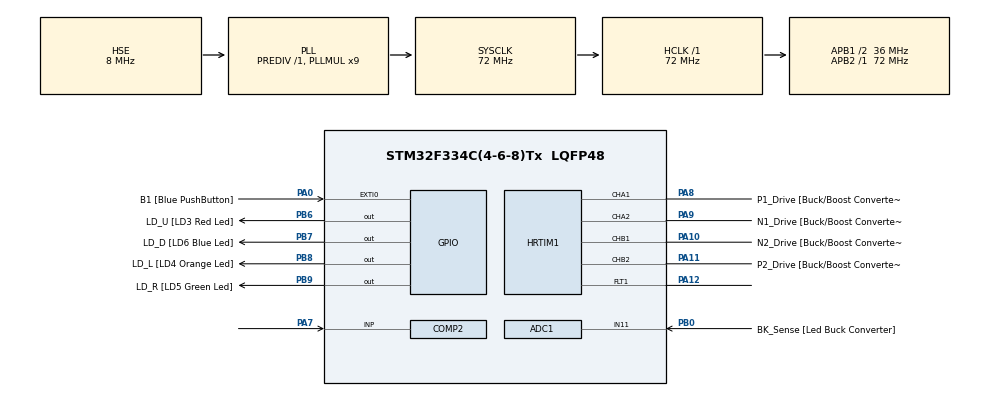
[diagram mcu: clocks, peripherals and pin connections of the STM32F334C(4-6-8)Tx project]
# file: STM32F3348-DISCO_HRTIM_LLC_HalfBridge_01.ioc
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ADC1.Channel-0\#ChannelRegularConversion=ADC_CHANNEL_11
ADC1.Channel-IN11=ADC_CHANNEL_11
ADC1.SubFamily=STM32F334x8
ADC1.master=1
COMP2.InvertingInput=COMP_INVERTINGINPUT_DAC1_CH2
HRTIM1.ADCTrigger2_Source1=HRTIM_ADCTRIGGEREVENT24_TIMERB_CMP3
HRTIM1.ADCTrigger2_Source2=HRTIM_ADCTRIGGEREVENT24_TIMERB_CMP4
HRTIM1.ADCTrigger2_Source3=HRTIM_ADCTRIGGEREVENT24_TIMERB_CMP2
HRTIM1.ADCTrigger2_Source4=HRTIM_ADCTRIGGEREVENT24_TIMERB_PERIOD
HRTIM1.ADCTrigger4_Source1=HRTIM_ADCTRIGGEREVENT24_TIMERC_CMP2
HRTIM1.ADCTrigger4_Source2=HRTIM_ADCTRIGGEREVENT24_TIMERC_CMP3
HRTIM1.ADCTrigger4_Source3=HRTIM_ADCTRIGGEREVENT24_TIMERC_CMP4
HRTIM1.ADCTrigger4_Source4=HRTIM_ADCTRIGGEREVENT24_TIMERC_PERIOD
HRTIM1.ADCTrigger_Id2=HRTIM_ADCTRIGGER_2
HRTIM1.ADCTrigger_Id4=HRTIM_ADCTRIGGER_4
HRTIM1.CompareUnit1-MasterTimer=HRTIM_COMPAREUNIT_1
HRTIM1.CompareUnit1-Output_TA1TA2=HRTIM_COMPAREUNIT_1
HRTIM1.CompareUnit1-Output_TB1TB2=HRTIM_COMPAREUNIT_1
HRTIM1.CompareUnit2-MasterTimer=HRTIM_COMPAREUNIT_2
HRTIM1.CompareUnit2-No_output_TC=HRTIM_COMPAREUNIT_2
HRTIM1.CompareUnit2-Output_TB1TB2=HRTIM_COMPAREUNIT_2
HRTIM1.CompareUnit3-MasterTimer=HRTIM_COMPAREUNIT_3
HRTIM1.CompareUnit3-No_output_TC=HRTIM_COMPAREUNIT_3
HRTIM1.CompareUnit3-Output_TB1TB2=HRTIM_COMPAREUNIT_3
HRTIM1.CompareUnit4-MasterTimer=HRTIM_COMPAREUNIT_4
HRTIM1.CompareUnit4-No_output_TC=HRTIM_COMPAREUNIT_4
HRTIM1.CompareUnit4-Output_TB1TB2=HRTIM_COMPAREUNIT_4
HRTIM1.CompareValue1-Output_TB1TB2=(15 * LLC_PWM_PERIOD)/100
HRTIM1.CompareValue2-MasterTimer=(35 * LLC_PWM_PERIOD)/100 - ADC_CONVERSION_TIME
HRTIM1.CompareValue2-No_output_TC=(65 * LLC_PWM_PERIOD)/100 - ADC_CONVERSION_TIME
HRTIM1.CompareValue2-Output_TB1TB2=(35 * LLC_PWM_PERIOD)/100
HRTIM1.CompareValue3-MasterTimer=(65 * LLC_PWM_PERIOD)/100
HRTIM1.CompareValue3-No_output_TC=(65 * LLC_PWM_PERIOD)/100 + ADC_CONVERSION_TIME
HRTIM1.CompareValue3-Output_TB1TB2=(15 * LLC_PWM_PERIOD)/100 - ADC_CONVERSION_TIME
HRTIM1.CompareValue4-MasterTimer=(85 * LLC_PWM_PERIOD)/100
HRTIM1.CompareValue4-No_output_TC=(85 * LLC_PWM_PERIOD)/100 - ADC_CONVERSION_TIME
HRTIM1.CompareValue4-Output_TB1TB2=(15 * LLC_PWM_PERIOD)/100 + ADC_CONVERSION_TIME
HRTIM1.DeadTimeInsertion-Output_TA1TA2=HRTIM_TIMDEADTIMEINSERTION_ENABLED
HRTIM1.DeadTimeInsertion-Output_TB1TB2=HRTIM_TIMDEADTIMEINSERTION_DISABLED
HRTIM1.DelayedProtectionMode-Output_TA1TA2=HRTIM_TIMER_A_B_C_DELAYEDPROTECTION_DELAYEDBOTH_EEV6
HRTIM1.Event6-Output_TA1TA2=HRTIM_EVENT_6
HRTIM1.EventPrescaler=HRTIM_EVENTPRESCALER_DIV2
HRTIM1.Event_EEV1=__NULL
HRTIM1.Event_EEV6=HRTIM_EVENT_6
HRTIM1.FallingSignLock-Output_TA1TA2=HRTIM_TIMDEADTIME_FALLINGSIGNLOCK_READONLY
HRTIM1.FaultEnable_Source1-Output_TA1TA2=HRTIM_TIMFAULTENABLE_FAULT1
HRTIM1.FaultEnable_Source1-Output_TB1TB2=HRTIM_TIMFAULTENABLE_FAULT1
HRTIM1.Fault_Line1=HRTIM_FAULT_1
HRTIM1.Filter6-Output_TA1TA2=HRTIM_TIMEVENTFILTER_BLANKINGCMP1
HRTIM1.HalfModeEnable-MasterTimer=HRTIM_HALFMODE_ENABLED
HRTIM1.ModeTimeBase-No_output_TC=HRTIM_MODE_SINGLESHOT_RETRIGGERABLE
HRTIM1.ModeTimeBase-Output_TB1TB2=HRTIM_MODE_SINGLESHOT_RETRIGGERABLE
HRTIM1.NumberADCTriggerSource2=4
HRTIM1.NumberADCTriggerSource4=4
HRTIM1.NumberFaultEnable-Output_TA1TA2=1
HRTIM1.NumberFaultEnable-Output_TB1TB2=1
HRTIM1.NumberResetSource1-Output_TA1TA2=1
HRTIM1.NumberResetSource1-Output_TB1TB2=1
HRTIM1.NumberResetSource2_TB=1
HRTIM1.NumberResetTrigger-No_output_TC=1
HRTIM1.NumberResetTrigger-Output_TA1TA2=2
HRTIM1.NumberResetTrigger-Output_TB1TB2=1
HRTIM1.NumberSetSource1-Output_TA1TA2=1
HRTIM1.NumberSetSource1-Output_TB1TB2=1
HRTIM1.NumberSetSource2_TB=1
HRTIM1.NumberUpdateTrigger-Output_TA1TA2=1
HRTIM1.Periode_MASTER=LLC_PWM_PERIOD
HRTIM1.Periode_TA=LLC_PWM_PERIOD
HRTIM1.Periode_TB=(35 * LLC_PWM_PERIOD)/100 + ADC_CONVERSION_TIME
HRTIM1.Periode_TC=(85 * LLC_PWM_PERIOD)/100 + ADC_CONVERSION_TIME
HRTIM1.Polarity_FaultLine1=HRTIM_FAULTPOLARITY_LOW
HRTIM1.PreloadEnable-MasterTimer=HRTIM_PRELOAD_ENABLED
HRTIM1.PreloadEnable-No_output_TC=HRTIM_PRELOAD_ENABLED
HRTIM1.PreloadEnable-Output_TA1TA2=HRTIM_PRELOAD_ENABLED
HRTIM1.PreloadEnable-Output_TB1TB2=HRTIM_PRELOAD_ENABLED
HRTIM1.PrescalerFault=HRTIM_FAULTPRESCALER_DIV1
HRTIM1.RepetitionUpdate-MasterTimer=HRTIM_UPDATEONREPETITION_ENABLED
HRTIM1.ResetOutput1_Source1-Output_TA1TA2=HRTIM_OUTPUTRESET_MASTERCMP1
HRTIM1.ResetOutput1_Source1-Output_TB1TB2=HRTIM_OUTPUTRESET_TIMCMP2
HRTIM1.ResetOutput2_Source1-Output_TB1TB2=HRTIM_OUTPUTRESET_MASTERCMP4
HRTIM1.ResetTrigger1-No_output_TC=HRTIM_TIMRESETTRIGGER_MASTER_PER
HRTIM1.ResetTrigger1-Output_TA1TA2=HRTIM_TIMRESETTRIGGER_MASTER_PER
HRTIM1.ResetTrigger1-Output_TB1TB2=HRTIM_TIMRESETTRIGGER_MASTER_PER
HRTIM1.ResetTrigger2-Output_TA1TA2=HRTIM_TIMRESETTRIGGER_MASTER_CMP1
HRTIM1.RisingSignLock-Output_TA1TA2=HRTIM_TIMDEADTIME_RISINGSIGNLOCK_READONLY
HRTIM1.SetOutput1_Source1-Output_TA1TA2=HRTIM_OUTPUTSET_MASTERPER
HRTIM1.SetOutput1_Source1-Output_TB1TB2=HRTIM_OUTPUTSET_TIMCMP1
HRTIM1.SetOutput2_Source1-Output_TB1TB2=HRTIM_OUTPUTSET_MASTERCMP3
HRTIM1.UpdateTrigger1-Output_TA1TA2=HRTIM_TIMUPDATETRIGGER_MASTER
Mcu.Family=STM32F3
Mcu.Name=STM32F334C(4-6-8)Tx
Mcu.Package=LQFP48
Mcu.UserConstants=LLC_PWM_PERIOD,0xFFDF;ADC_CONVERSION_TIME,0x480
NVIC.HRTIM1_Master_IRQn=true\:0\:0\:false\:false\:true\:true\:true\:false
NVIC.PriorityGroup=NVIC_PRIORITYGROUP_0
PA0.GPIO_Label=B1 [Blue PushButton]
PA0.GPIO_ModeDefaultEXTI=GPIO_MODE_EVT_RISING
PA0.GPIO_PuPd=GPIO_NOPULL
PA0.Signal=GPXTI0
PA1.GPIO_Label=Vin_Sense [Buck/Boost Converter]
PA1.GPIO_Mode=GPIO_MODE_ANALOG
PA1.GPIO_PuPd=GPIO_NOPULL
PA1.Signal=ADC1_IN2
PA10.GPIO_Label=N2_Drive [Buck/Boost Converter]
PA10.GPIO_ModeDefaultPP=GPIO_MODE_AF_PP
PA10.GPIO_PuPd=GPIO_NOPULL
PA10.GPIO_Speed=GPIO_SPEED_FREQ_LOW
PA10.Mode=Output_TB1TB2
PA10.Signal=HRTIM1_CHB1
PA11.GPIO_Label=P2_Drive [Buck/Boost Converter]
PA11.GPIO_ModeDefaultPP=GPIO_MODE_AF_PP
PA11.GPIO_PuPd=GPIO_NOPULL
PA11.GPIO_Speed=GPIO_SPEED_FREQ_LOW
PA11.Mode=Output_TB1TB2
PA11.Signal=HRTIM1_CHB2
PA12.Mode=Fault_Enable1
PA12.Signal=HRTIM1_FLT1
PA13.GPIO_Label=SWDIO
PA13.Mode=Serial_Wire
PA13.Signal=SYS_JTMS-SWDIO
PA14.GPIO_Label=SWCLK
PA14.Mode=Serial_Wire
PA14.Signal=SYS_JTCK-SWCLK
PA3.GPIO_Label=Vout_Sense [Buck/Boost Converter]
PA3.GPIO_Mode=GPIO_MODE_ANALOG
PA3.GPIO_PuPd=GPIO_NOPULL
PA3.Signal=ADC1_IN4
PA7.Mode=INP
PA7.Signal=COMP2_INP
PA8.GPIO_Label=P1_Drive [Buck/Boost Converter]
PA8.GPIO_ModeDefaultPP=GPIO_MODE_AF_PP
PA8.GPIO_PuPd=GPIO_NOPULL
PA8.GPIO_Speed=GPIO_SPEED_FREQ_LOW
PA8.Mode=Output_TA1TA2
PA8.Signal=HRTIM1_CHA1
PA9.GPIO_Label=N1_Drive [Buck/Boost Converter]
PA9.GPIO_ModeDefaultPP=GPIO_MODE_AF_PP
PA9.GPIO_PuPd=GPIO_NOPULL
PA9.GPIO_Speed=GPIO_SPEED_FREQ_LOW
PA9.Mode=Output_TA1TA2
PA9.Signal=HRTIM1_CHA2
PB0.GPIO_Label=BK_Sense [Led Buck Converter]
PB0.GPIO_Mode=GPIO_MODE_ANALOG
PB0.GPIO_PuPd=GPIO_NOPULL
PB0.Mode=IN11-Single-Ended
PB0.Signal=ADC1_IN11
PB12.GPIO_Label=BK_Drive [Led Buck Converter]
PB12.GPIO_ModeDefaultPP=GPIO_MODE_AF_PP
PB12.GPIO_PuPd=GPIO_NOPULL
PB12.GPIO_Speed=GPIO_SPEED_FREQ_LOW
PB12.Signal=HRTIM1_CHC1
PB14.GPIO_Label=RC [Buck/Boost Converter]
PB14.Signal=HRTIM1_CHD1
PB6.GPIO_FM6=__NULL
PB6.GPIO_Label=LD_U [LD3 Red Led]
PB6.GPIO_ModeDefaultOutputPP=GPIO_MODE_OUTPUT_PP
PB6.GPIO_PuPd=GPIO_NOPULL
PB6.GPIO_Speed=GPIO_SPEED_FREQ_LOW
PB6.Signal=GPIO_Output
PB7.GPIO_FM7=__NULL
PB7.GPIO_Label=LD_D [LD6 Blue Led]
PB7.GPIO_ModeDefaultOutputPP=GPIO_MODE_OUTPUT_PP
PB7.GPIO_PuPd=GPIO_NOPULL
PB7.GPIO_Speed=GPIO_SPEED_FREQ_LOW
PB7.Signal=GPIO_Output
PB8.GPIO_FM8=__NULL
PB8.GPIO_Label=LD_L [LD4 Orange Led]
PB8.GPIO_ModeDefaultOutputPP=GPIO_MODE_OUTPUT_PP
PB8.GPIO_PuPd=GPIO_NOPULL
PB8.GPIO_Speed=GPIO_SPEED_FREQ_LOW
PB8.Signal=GPIO_Output
PB9.GPIO_FM9=__NULL
PB9.GPIO_Label=LD_R [LD5 Green Led]
PB9.GPIO_ModeDefaultOutputPP=GPIO_MODE_OUTPUT_PP
PB9.GPIO_PuPd=GPIO_NOPULL
PB9.GPIO_Speed=GPIO_SPEED_FREQ_LOW
PB9.Signal=GPIO_Output
PF0\ /\ OSC_IN.GPIO_Label=PF0-OSC_IN
PF0\ /\ OSC_IN.Mode=HSE-External-Clock-Source
PF0\ /\ OSC_IN.Signal=RCC_OSC_IN
PF1\ /\ OSC_OUT.GPIO_Label=PF1_OSC_OUT
PF1\ /\ OSC_OUT.Signal=RCC_OSC_OUT
ProjectManager.HeapSize=0x200
ProjectManager.StackSize=0x400
ProjectManager.TargetToolchain=STM32CubeIDE
RCC.AHBFreq_Value=72000000
RCC.APB1CLKDivider=RCC_HCLK_DIV2
RCC.APB1Freq_Value=36000000
RCC.APB1TimFreq_Value=72000000
RCC.APB2Freq_Value=72000000
RCC.APB2TimFreq_Value=72000000
RCC.CortexFreq_Value=72000000
RCC.HCLKFreq_Value=72000000
RCC.HRTIMSelection=RCC_HRTIM1CLK_PLLCLK
RCC.HSE_VALUE=8000000
RCC.HSI_VALUE=8000000
RCC.LSE_VALUE=32768
RCC.PLLMUL=RCC_PLL_MUL9
RCC.PLLSourceVirtual=RCC_PLLSOURCE_HSE
RCC.SYSCLKFreq_VALUE=72000000
RCC.SYSCLKSourceVirtual=RCC_SYSCLKSOURCE_PLLCLK
VP_COMP2_VS_DAC1OUT2.Mode=INM_DAC1OUT2
VP_DAC1_Switcher_Out2.Mode=Switch_Disable_OUT2
VP_HRTIM1_VS_hrtimMasterTimerNoOutput.Mode=MasterTimer
VP_HRTIM1_VS_hrtimTimerCNoOutput.Mode=No_output_TC
board=STM32F3348-DISCO

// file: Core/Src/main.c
/* USER CODE BEGIN Header */
/**
  ******************************************************************************
  * @file           : main.c
  * @brief          : Main program body
  ******************************************************************************
  * @attention
  *
  * Copyright (c) 2022 STMicroelectronics.
  * All rights reserved.
  *
  * This software is licensed under terms that can be found in the LICENSE file
  * in the root directory of this software component.
  * If no LICENSE file comes with this software, it is provided AS-IS.
  *
  ******************************************************************************
  */
/* USER CODE END Header */
#include "main.h"

ADC_HandleTypeDef hadc1;

COMP_HandleTypeDef hcomp2;

DAC_HandleTypeDef hdac1;

HRTIM_HandleTypeDef hhrtim1;

void SystemClock_Config(void);
static void MX_GPIO_Init(void);
static void MX_ADC1_Init(void);
static void MX_HRTIM1_Init(void);
static void MX_COMP2_Init(void);
static void MX_DAC1_Init(void);

int main(void)
{

  /* MCU Configuration--------------------------------------------------------*/

  /* Reset of all peripherals, Initializes the Flash interface and the Systick. */
  HAL_Init();

  /* Configure the system clock */
  SystemClock_Config();

  /* Initialize all configured peripherals */
  MX_GPIO_Init();
  MX_ADC1_Init();
  MX_HRTIM1_Init();
  MX_COMP2_Init();
  MX_DAC1_Init();

  /* Infinite loop */
  while (1)
  {

  }
}

void SystemClock_Config(void)
{
  RCC_OscInitTypeDef RCC_OscInitStruct = {0};
  RCC_ClkInitTypeDef RCC_ClkInitStruct = {0};
  RCC_PeriphCLKInitTypeDef PeriphClkInit = {0};

  /** Initializes the RCC Oscillators according to the specified parameters
  * in the RCC_OscInitTypeDef structure.
  */
  RCC_OscInitStruct.OscillatorType = RCC_OSCILLATORTYPE_HSE;
  RCC_OscInitStruct.HSEState = RCC_HSE_BYPASS;
  RCC_OscInitStruct.HSEPredivValue = RCC_HSE_PREDIV_DIV1;
  RCC_OscInitStruct.HSIState = RCC_HSI_ON;
  RCC_OscInitStruct.PLL.PLLState = RCC_PLL_ON;
  RCC_OscInitStruct.PLL.PLLSource = RCC_PLLSOURCE_HSE;
  RCC_OscInitStruct.PLL.PLLMUL = RCC_PLL_MUL9;
  if (HAL_RCC_OscConfig(&RCC_OscInitStruct) != HAL_OK)
  {
    Error_Handler();
  }

  /** Initializes the CPU, AHB and APB buses clocks
  */
  RCC_ClkInitStruct.ClockType = RCC_CLOCKTYPE_HCLK|RCC_CLOCKTYPE_SYSCLK
                              |RCC_CLOCKTYPE_PCLK1|RCC_CLOCKTYPE_PCLK2;
  RCC_ClkInitStruct.SYSCLKSource = RCC_SYSCLKSOURCE_PLLCLK;
  RCC_ClkInitStruct.AHBCLKDivider = RCC_SYSCLK_DIV1;
  RCC_ClkInitStruct.APB1CLKDivider = RCC_HCLK_DIV2;
  RCC_ClkInitStruct.APB2CLKDivider = RCC_HCLK_DIV1;

  if (HAL_RCC_ClockConfig(&RCC_ClkInitStruct, FLASH_LATENCY_2) != HAL_OK)
  {
    Error_Handler();
  }
  PeriphClkInit.PeriphClockSelection = RCC_PERIPHCLK_HRTIM1|RCC_PERIPHCLK_ADC12;
  PeriphClkInit.Adc12ClockSelection = RCC_ADC12PLLCLK_DIV1;
  PeriphClkInit.Hrtim1ClockSelection = RCC_HRTIM1CLK_PLLCLK;
  if (HAL_RCCEx_PeriphCLKConfig(&PeriphClkInit) != HAL_OK)
  {
    Error_Handler();
  }
}

static void MX_ADC1_Init(void)
{

  ADC_MultiModeTypeDef multimode = {0};
  ADC_ChannelConfTypeDef sConfig = {0};

  /** Common config
  */
  hadc1.Instance = ADC1;
  hadc1.Init.ClockPrescaler = ADC_CLOCK_ASYNC_DIV1;
  hadc1.Init.Resolution = ADC_RESOLUTION_12B;
  hadc1.Init.ScanConvMode = ADC_SCAN_DISABLE;
  hadc1.Init.ContinuousConvMode = DISABLE;
  hadc1.Init.DiscontinuousConvMode = DISABLE;
  hadc1.Init.ExternalTrigConvEdge = ADC_EXTERNALTRIGCONVEDGE_NONE;
  hadc1.Init.ExternalTrigConv = ADC_SOFTWARE_START;
  hadc1.Init.DataAlign = ADC_DATAALIGN_RIGHT;
  hadc1.Init.NbrOfConversion = 1;
  hadc1.Init.DMAContinuousRequests = DISABLE;
  hadc1.Init.EOCSelection = ADC_EOC_SINGLE_CONV;
  hadc1.Init.LowPowerAutoWait = DISABLE;
  hadc1.Init.Overrun = ADC_OVR_DATA_OVERWRITTEN;
  if (HAL_ADC_Init(&hadc1) != HAL_OK)
  {
    Error_Handler();
  }

  /** Configure the ADC multi-mode
  */
  multimode.Mode = ADC_MODE_INDEPENDENT;
  if (HAL_ADCEx_MultiModeConfigChannel(&hadc1, &multimode) != HAL_OK)
  {
    Error_Handler();
  }

  /** Configure Regular Channel
  */
  sConfig.Channel = ADC_CHANNEL_11;
  sConfig.Rank = ADC_REGULAR_RANK_1;
  sConfig.SingleDiff = ADC_SINGLE_ENDED;
  sConfig.SamplingTime = ADC_SAMPLETIME_1CYCLE_5;
  sConfig.OffsetNumber = ADC_OFFSET_NONE;
  sConfig.Offset = 0;
  if (HAL_ADC_ConfigChannel(&hadc1, &sConfig) != HAL_OK)
  {
    Error_Handler();
  }

}

static void MX_COMP2_Init(void)
{

  hcomp2.Instance = COMP2;
  hcomp2.Init.InvertingInput = COMP_INVERTINGINPUT_DAC1_CH2;
  hcomp2.Init.NonInvertingInput = COMP_NONINVERTINGINPUT_IO1;
  hcomp2.Init.Output = COMP_OUTPUT_NONE;
  hcomp2.Init.OutputPol = COMP_OUTPUTPOL_NONINVERTED;
  hcomp2.Init.BlankingSrce = COMP_BLANKINGSRCE_NONE;
  hcomp2.Init.TriggerMode = COMP_TRIGGERMODE_NONE;
  if (HAL_COMP_Init(&hcomp2) != HAL_OK)
  {
    Error_Handler();
  }
  /* USER CODE BEGIN COMP2_Init 2 */

  // below are from >> STM32F3348-Discovery\Examples\HRTIM\HRTIM_LLC_HalfBridge
  // added here for reference and some are commented because already initialized above
//  /*##-1- Configure the COMP2 peripheral ###################################*/
//  Comp2Handle.Instance = COMP2;
//
//  Comp2Handle.Init.InvertingInput    = COMP_INVERTINGINPUT_DAC1_CH2;
//  Comp2Handle.Init.NonInvertingInput = COMP_NONINVERTINGINPUT_IO1;
//  Comp2Handle.Init.Output            = COMP_OUTPUT_NONE;
//  Comp2Handle.Init.OutputPol         = COMP_OUTPUTPOL_NONINVERTED;
//  Comp2Handle.Init.BlankingSrce      = COMP_BLANKINGSRCE_NONE;
//  Comp2Handle.Init.Hysteresis        = COMP_HYSTERESIS_NONE;
//  Comp2Handle.Init.WindowMode        = COMP_WINDOWMODE_DISABLE;
//  Comp2Handle.Init.TriggerMode       = COMP_TRIGGERMODE_NONE;
//  HAL_COMP_Init(&Comp2Handle);
//
//  /*##-2- Start the comparator process #####################################*/
//  /* Enable COMP2 */
  HAL_COMP_Start(&hcomp2); // from >> STM32F3348-Discovery\Examples\HRTIM\HRTIM_LLC_HalfBridge

  /* USER CODE END COMP2_Init 2 */

}

static void MX_DAC1_Init(void)
{

  DAC_ChannelConfTypeDef sConfig = {0};

  /** DAC Initialization
  */
  hdac1.Instance = DAC1;
  if (HAL_DAC_Init(&hdac1) != HAL_OK)
  {
    Error_Handler();
  }

  /** DAC channel OUT2 config
  */
  sConfig.DAC_Trigger = DAC_TRIGGER_NONE;
  sConfig.DAC_OutputSwitch = DAC_OUTPUTSWITCH_DISABLE;
  if (HAL_DAC_ConfigChannel(&hdac1, &sConfig, DAC_CHANNEL_2) != HAL_OK)
  {
    Error_Handler();
  }
  /* USER CODE BEGIN DAC1_Init 2 */

  // below are from >> STM32F3348-Discovery\Examples\HRTIM\HRTIM_LLC_HalfBridge
  // some are commented because already initialized above
//  static DAC_ChannelConfTypeDef sConfig;
//
//  /*##-1- Configure the DAC peripheral #######################################*/
//  DacHandle.Instance = DAC1;
//
//  if (HAL_DAC_Init(&DacHandle) != HAL_OK)
//  {
//    /* Initiliazation Error */
//    Error_Handler();
//  }
//
//  /*##-2- Configure DAC channel1 #############################################*/
//  sConfig.DAC_Trigger = DAC_TRIGGER_NONE;
//  sConfig.DAC_OutputBuffer = DAC_OUTPUTBUFFER_DISABLE;
//
//  if (HAL_DAC_ConfigChannel(&DacHandle, &sConfig, DAC_CHANNEL_2) != HAL_OK)
//  {
//    /* Channel configuration Error */
//    Error_Handler();
//  }

  /*##-3- Set DAC Channel1 DHR register ######################################*/
  // from >> STM32F3348-Discovery\Examples\HRTIM\HRTIM_LLC_HalfBridge
  if (HAL_DAC_SetValue(&hdac1, DAC_CHANNEL_2, DAC_ALIGN_12B_R, 0x4FF) != HAL_OK)
  {
    /* Setting value Error */
    Error_Handler();
  }

  /*##-4- Enable DAC Channel1 ################################################*/
  // from >> STM32F3348-Discovery\Examples\HRTIM\HRTIM_LLC_HalfBridge
  if (HAL_DAC_Start(&hdac1, DAC_CHANNEL_2) != HAL_OK)
  {
    /* Start Error */
    Error_Handler();
  }
  /* USER CODE END DAC1_Init 2 */

}

static void MX_HRTIM1_Init(void)
{

  HRTIM_EventCfgTypeDef pEventCfg = {0};
  HRTIM_FaultCfgTypeDef pFaultCfg = {0};
  HRTIM_ADCTriggerCfgTypeDef pADCTriggerCfg = {0};
  HRTIM_TimeBaseCfgTypeDef pTimeBaseCfg = {0};
  HRTIM_TimerCfgTypeDef pTimerCfg = {0};
  HRTIM_CompareCfgTypeDef pCompareCfg = {0};
  HRTIM_TimerEventFilteringCfgTypeDef pTimerEventFilteringCfg = {0};
  HRTIM_DeadTimeCfgTypeDef pDeadTimeCfg = {0};
  HRTIM_OutputCfgTypeDef pOutputCfg = {0};

  hhrtim1.Instance = HRTIM1;
  hhrtim1.Init.HRTIMInterruptResquests = HRTIM_IT_NONE;
  hhrtim1.Init.SyncOptions = HRTIM_SYNCOPTION_NONE;
  if (HAL_HRTIM_Init(&hhrtim1) != HAL_OK)
  {
    Error_Handler();
  }
  if (HAL_HRTIM_DLLCalibrationStart(&hhrtim1, HRTIM_CALIBRATIONRATE_14) != HAL_OK)
  {
    Error_Handler();
  }
  if (HAL_HRTIM_PollForDLLCalibration(&hhrtim1, 10) != HAL_OK)
  {
    Error_Handler();
  }
  if (HAL_HRTIM_EventPrescalerConfig(&hhrtim1, HRTIM_EVENTPRESCALER_DIV2) != HAL_OK)
  {
    Error_Handler();
  }
  pEventCfg.Source = HRTIM_EVENTSRC_2;
  pEventCfg.Polarity = HRTIM_EVENTPOLARITY_HIGH;
  pEventCfg.Sensitivity = HRTIM_EVENTSENSITIVITY_LEVEL;
  pEventCfg.Filter = HRTIM_EVENTFILTER_NONE;
  if (HAL_HRTIM_EventConfig(&hhrtim1, HRTIM_EVENT_6, &pEventCfg) != HAL_OK)
  {
    Error_Handler();
  }
  if (HAL_HRTIM_FaultPrescalerConfig(&hhrtim1, HRTIM_FAULTPRESCALER_DIV1) != HAL_OK)
  {
    Error_Handler();
  }
  pFaultCfg.Source = HRTIM_FAULTSOURCE_DIGITALINPUT;
  pFaultCfg.Polarity = HRTIM_FAULTPOLARITY_LOW;
  pFaultCfg.Filter = HRTIM_FAULTFILTER_NONE;
  pFaultCfg.Lock = HRTIM_FAULTLOCK_READWRITE;
  if (HAL_HRTIM_FaultConfig(&hhrtim1, HRTIM_FAULT_1, &pFaultCfg) != HAL_OK)
  {
    Error_Handler();
  }
  HAL_HRTIM_FaultModeCtl(&hhrtim1, HRTIM_FAULT_1, HRTIM_FAULTMODECTL_ENABLED);
  pADCTriggerCfg.UpdateSource = HRTIM_ADCTRIGGERUPDATE_MASTER;
  pADCTriggerCfg.Trigger = HRTIM_ADCTRIGGEREVENT24_TIMERB_CMP3|HRTIM_ADCTRIGGEREVENT24_TIMERB_CMP4
                              |HRTIM_ADCTRIGGEREVENT24_TIMERB_CMP2|HRTIM_ADCTRIGGEREVENT24_TIMERB_PERIOD;
  if (HAL_HRTIM_ADCTriggerConfig(&hhrtim1, HRTIM_ADCTRIGGER_2, &pADCTriggerCfg) != HAL_OK)
  {
    Error_Handler();
  }
  pADCTriggerCfg.Trigger = HRTIM_ADCTRIGGEREVENT24_TIMERC_CMP2|HRTIM_ADCTRIGGEREVENT24_TIMERC_CMP3
                              |HRTIM_ADCTRIGGEREVENT24_TIMERC_CMP4|HRTIM_ADCTRIGGEREVENT24_TIMERC_PERIOD;
  if (HAL_HRTIM_ADCTriggerConfig(&hhrtim1, HRTIM_ADCTRIGGER_4, &pADCTriggerCfg) != HAL_OK)
  {
    Error_Handler();
  }
  pTimeBaseCfg.Period = LLC_PWM_PERIOD;
  pTimeBaseCfg.RepetitionCounter = 0x00;
  pTimeBaseCfg.PrescalerRatio = HRTIM_PRESCALERRATIO_MUL32;
  pTimeBaseCfg.Mode = HRTIM_MODE_CONTINUOUS;
  if (HAL_HRTIM_TimeBaseConfig(&hhrtim1, HRTIM_TIMERINDEX_MASTER, &pTimeBaseCfg) != HAL_OK)
  {
    Error_Handler();
  }
  pTimerCfg.InterruptRequests = HRTIM_MASTER_IT_NONE;
  pTimerCfg.DMARequests = HRTIM_MASTER_DMA_NONE;
  pTimerCfg.DMASrcAddress = 0x0000;
  pTimerCfg.DMADstAddress = 0x0000;
  pTimerCfg.DMASize = 0x1;
  pTimerCfg.HalfModeEnable = HRTIM_HALFMODE_ENABLED;
  pTimerCfg.StartOnSync = HRTIM_SYNCSTART_DISABLED;
  pTimerCfg.ResetOnSync = HRTIM_SYNCRESET_DISABLED;
  pTimerCfg.DACSynchro = HRTIM_DACSYNC_NONE;
  pTimerCfg.PreloadEnable = HRTIM_PRELOAD_ENABLED;
  pTimerCfg.UpdateGating = HRTIM_UPDATEGATING_INDEPENDENT;
  pTimerCfg.BurstMode = HRTIM_TIMERBURSTMODE_MAINTAINCLOCK;
  pTimerCfg.RepetitionUpdate = HRTIM_UPDATEONREPETITION_ENABLED;
  if (HAL_HRTIM_WaveformTimerConfig(&hhrtim1, HRTIM_TIMERINDEX_MASTER, &pTimerCfg) != HAL_OK)
  {
    Error_Handler();
  }
  pCompareCfg.CompareValue = (35 * LLC_PWM_PERIOD)/100 - ADC_CONVERSION_TIME;
  if (HAL_HRTIM_WaveformCompareConfig(&hhrtim1, HRTIM_TIMERINDEX_MASTER, HRTIM_COMPAREUNIT_2, &pCompareCfg) != HAL_OK)
  {
    Error_Handler();
  }
  pCompareCfg.CompareValue = (65 * LLC_PWM_PERIOD)/100;
  if (HAL_HRTIM_WaveformCompareConfig(&hhrtim1, HRTIM_TIMERINDEX_MASTER, HRTIM_COMPAREUNIT_3, &pCompareCfg) != HAL_OK)
  {
    Error_Handler();
  }
  pCompareCfg.CompareValue = (85 * LLC_PWM_PERIOD)/100;
  if (HAL_HRTIM_WaveformCompareConfig(&hhrtim1, HRTIM_TIMERINDEX_MASTER, HRTIM_COMPAREUNIT_4, &pCompareCfg) != HAL_OK)
  {
    Error_Handler();
  }
  if (HAL_HRTIM_TimeBaseConfig(&hhrtim1, HRTIM_TIMERINDEX_TIMER_A, &pTimeBaseCfg) != HAL_OK)
  {
    Error_Handler();
  }
  pTimerCfg.InterruptRequests = HRTIM_TIM_IT_NONE;
  pTimerCfg.DMARequests = HRTIM_TIM_DMA_NONE;
  pTimerCfg.HalfModeEnable = HRTIM_HALFMODE_DISABLED;
  pTimerCfg.RepetitionUpdate = HRTIM_UPDATEONREPETITION_DISABLED;
  pTimerCfg.PushPull = HRTIM_TIMPUSHPULLMODE_DISABLED;
  pTimerCfg.FaultEnable = HRTIM_TIMFAULTENABLE_FAULT1;
  pTimerCfg.FaultLock = HRTIM_TIMFAULTLOCK_READWRITE;
  pTimerCfg.DeadTimeInsertion = HRTIM_TIMDEADTIMEINSERTION_ENABLED;
  pTimerCfg.DelayedProtectionMode = HRTIM_TIMER_A_B_C_DELAYEDPROTECTION_DELAYEDBOTH_EEV6;
  pTimerCfg.UpdateTrigger = HRTIM_TIMUPDATETRIGGER_MASTER;
  pTimerCfg.ResetTrigger = HRTIM_TIMRESETTRIGGER_MASTER_PER|HRTIM_TIMRESETTRIGGER_MASTER_CMP1;
  pTimerCfg.ResetUpdate = HRTIM_TIMUPDATEONRESET_DISABLED;
  if (HAL_HRTIM_WaveformTimerConfig(&hhrtim1, HRTIM_TIMERINDEX_TIMER_A, &pTimerCfg) != HAL_OK)
  {
    Error_Handler();
  }
  pTimerCfg.DeadTimeInsertion = HRTIM_TIMDEADTIMEINSERTION_DISABLED;
  pTimerCfg.DelayedProtectionMode = HRTIM_TIMER_A_B_C_DELAYEDPROTECTION_DISABLED;
  pTimerCfg.UpdateTrigger = HRTIM_TIMUPDATETRIGGER_NONE;
  pTimerCfg.ResetTrigger = HRTIM_TIMRESETTRIGGER_MASTER_PER;
  if (HAL_HRTIM_WaveformTimerConfig(&hhrtim1, HRTIM_TIMERINDEX_TIMER_B, &pTimerCfg) != HAL_OK)
  {
    Error_Handler();
  }
  pTimerCfg.FaultEnable = HRTIM_TIMFAULTENABLE_NONE;
  if (HAL_HRTIM_WaveformTimerConfig(&hhrtim1, HRTIM_TIMERINDEX_TIMER_C, &pTimerCfg) != HAL_OK)
  {
    Error_Handler();
  }
  pCompareCfg.CompareValue = 0xFFDF;
  if (HAL_HRTIM_WaveformCompareConfig(&hhrtim1, HRTIM_TIMERINDEX_TIMER_A, HRTIM_COMPAREUNIT_1, &pCompareCfg) != HAL_OK)
  {
    Error_Handler();
  }
  pCompareCfg.CompareValue = (35 * LLC_PWM_PERIOD)/100;
  pCompareCfg.AutoDelayedMode = HRTIM_AUTODELAYEDMODE_REGULAR;
  pCompareCfg.AutoDelayedTimeout = 0x0000;

  if (HAL_HRTIM_WaveformCompareConfig(&hhrtim1, HRTIM_TIMERINDEX_TIMER_B, HRTIM_COMPAREUNIT_2, &pCompareCfg) != HAL_OK)
  {
    Error_Handler();
  }
  pCompareCfg.CompareValue = (65 * LLC_PWM_PERIOD)/100 - ADC_CONVERSION_TIME;

  if (HAL_HRTIM_WaveformCompareConfig(&hhrtim1, HRTIM_TIMERINDEX_TIMER_C, HRTIM_COMPAREUNIT_2, &pCompareCfg) != HAL_OK)
  {
    Error_Handler();
  }
  pCompareCfg.CompareValue = (15 * LLC_PWM_PERIOD)/100 + ADC_CONVERSION_TIME;

  if (HAL_HRTIM_WaveformCompareConfig(&hhrtim1, HRTIM_TIMERINDEX_TIMER_B, HRTIM_COMPAREUNIT_4, &pCompareCfg) != HAL_OK)
  {
    Error_Handler();
  }
  pCompareCfg.CompareValue = (85 * LLC_PWM_PERIOD)/100 - ADC_CONVERSION_TIME;

  if (HAL_HRTIM_WaveformCompareConfig(&hhrtim1, HRTIM_TIMERINDEX_TIMER_C, HRTIM_COMPAREUNIT_4, &pCompareCfg) != HAL_OK)
  {
    Error_Handler();
  }
  pTimerEventFilteringCfg.Filter = HRTIM_TIMEVENTFILTER_BLANKINGCMP1;
  pTimerEventFilteringCfg.Latch = HRTIM_TIMEVENTLATCH_DISABLED;
  if (HAL_HRTIM_TimerEventFilteringConfig(&hhrtim1, HRTIM_TIMERINDEX_TIMER_A, HRTIM_EVENT_6, &pTimerEventFilteringCfg) != HAL_OK)
  {
    Error_Handler();
  }
  pDeadTimeCfg.Prescaler = HRTIM_TIMDEADTIME_PRESCALERRATIO_MUL8;
  pDeadTimeCfg.RisingValue = 0x000;
  pDeadTimeCfg.RisingSign = HRTIM_TIMDEADTIME_RISINGSIGN_POSITIVE;
  pDeadTimeCfg.RisingLock = HRTIM_TIMDEADTIME_RISINGLOCK_WRITE;
  pDeadTimeCfg.RisingSignLock = HRTIM_TIMDEADTIME_RISINGSIGNLOCK_READONLY;
  pDeadTimeCfg.FallingValue = 0x000;
  pDeadTimeCfg.FallingSign = HRTIM_TIMDEADTIME_FALLINGSIGN_POSITIVE;
  pDeadTimeCfg.FallingLock = HRTIM_TIMDEADTIME_FALLINGLOCK_WRITE;
  pDeadTimeCfg.FallingSignLock = HRTIM_TIMDEADTIME_FALLINGSIGNLOCK_READONLY;
  if (HAL_HRTIM_DeadTimeConfig(&hhrtim1, HRTIM_TIMERINDEX_TIMER_A, &pDeadTimeCfg) != HAL_OK)
  {
    Error_Handler();
  }
  pOutputCfg.Polarity = HRTIM_OUTPUTPOLARITY_HIGH;
  pOutputCfg.SetSource = HRTIM_OUTPUTSET_MASTERPER;
  pOutputCfg.ResetSource = HRTIM_OUTPUTRESET_MASTERCMP1;
  pOutputCfg.IdleMode = HRTIM_OUTPUTIDLEMODE_NONE;
  pOutputCfg.IdleLevel = HRTIM_OUTPUTIDLELEVEL_INACTIVE;
  pOutputCfg.FaultLevel = HRTIM_OUTPUTFAULTLEVEL_NONE;
  pOutputCfg.ChopperModeEnable = HRTIM_OUTPUTCHOPPERMODE_DISABLED;
  pOutputCfg.BurstModeEntryDelayed = HRTIM_OUTPUTBURSTMODEENTRY_REGULAR;
  if (HAL_HRTIM_WaveformOutputConfig(&hhrtim1, HRTIM_TIMERINDEX_TIMER_A, HRTIM_OUTPUT_TA1, &pOutputCfg) != HAL_OK)
  {
    Error_Handler();
  }
  pOutputCfg.SetSource = HRTIM_OUTPUTSET_TIMCMP1;
  pOutputCfg.ResetSource = HRTIM_OUTPUTRESET_TIMCMP2;
  if (HAL_HRTIM_WaveformOutputConfig(&hhrtim1, HRTIM_TIMERINDEX_TIMER_B, HRTIM_OUTPUT_TB1, &pOutputCfg) != HAL_OK)
  {
    Error_Handler();
  }
  pOutputCfg.SetSource = HRTIM_OUTPUTSET_NONE;
  pOutputCfg.ResetSource = HRTIM_OUTPUTRESET_NONE;
  if (HAL_HRTIM_WaveformOutputConfig(&hhrtim1, HRTIM_TIMERINDEX_TIMER_A, HRTIM_OUTPUT_TA2, &pOutputCfg) != HAL_OK)
  {
    Error_Handler();
  }
  pOutputCfg.SetSource = HRTIM_OUTPUTSET_MASTERCMP3;
  pOutputCfg.ResetSource = HRTIM_OUTPUTRESET_MASTERCMP4;
  if (HAL_HRTIM_WaveformOutputConfig(&hhrtim1, HRTIM_TIMERINDEX_TIMER_B, HRTIM_OUTPUT_TB2, &pOutputCfg) != HAL_OK)
  {
    Error_Handler();
  }
  pTimeBaseCfg.Period = (35 * LLC_PWM_PERIOD)/100 + ADC_CONVERSION_TIME;
  pTimeBaseCfg.Mode = HRTIM_MODE_SINGLESHOT_RETRIGGERABLE;
  if (HAL_HRTIM_TimeBaseConfig(&hhrtim1, HRTIM_TIMERINDEX_TIMER_B, &pTimeBaseCfg) != HAL_OK)
  {
    Error_Handler();
  }
  pCompareCfg.CompareValue = (15 * LLC_PWM_PERIOD)/100;
  if (HAL_HRTIM_WaveformCompareConfig(&hhrtim1, HRTIM_TIMERINDEX_TIMER_B, HRTIM_COMPAREUNIT_1, &pCompareCfg) != HAL_OK)
  {
    Error_Handler();
  }
  pCompareCfg.CompareValue = (15 * LLC_PWM_PERIOD)/100 - ADC_CONVERSION_TIME;
  if (HAL_HRTIM_WaveformCompareConfig(&hhrtim1, HRTIM_TIMERINDEX_TIMER_B, HRTIM_COMPAREUNIT_3, &pCompareCfg) != HAL_OK)
  {
    Error_Handler();
  }
  pTimeBaseCfg.Period = (85 * LLC_PWM_PERIOD)/100 + ADC_CONVERSION_TIME;
  if (HAL_HRTIM_TimeBaseConfig(&hhrtim1, HRTIM_TIMERINDEX_TIMER_C, &pTimeBaseCfg) != HAL_OK)
  {
    Error_Handler();
  }
  pCompareCfg.CompareValue = (65 * LLC_PWM_PERIOD)/100 + ADC_CONVERSION_TIME;
  if (HAL_HRTIM_WaveformCompareConfig(&hhrtim1, HRTIM_TIMERINDEX_TIMER_C, HRTIM_COMPAREUNIT_3, &pCompareCfg) != HAL_OK)
  {
    Error_Handler();
  }
  HAL_HRTIM_MspPostInit(&hhrtim1);

}

static void MX_GPIO_Init(void)
{
  GPIO_InitTypeDef GPIO_InitStruct = {0};

  /* GPIO Ports Clock Enable */
  __HAL_RCC_GPIOF_CLK_ENABLE();
  __HAL_RCC_GPIOA_CLK_ENABLE();
  __HAL_RCC_GPIOB_CLK_ENABLE();

  /*Configure GPIO pin Output Level */
  HAL_GPIO_WritePin(GPIOB, LD_U_Pin|LD_D_Pin|LD_L_Pin|LD_R_Pin, GPIO_PIN_RESET);

  /*Configure GPIO pin : B1_Pin */
  GPIO_InitStruct.Pin = B1_Pin;
  GPIO_InitStruct.Mode = GPIO_MODE_EVT_RISING;
  GPIO_InitStruct.Pull = GPIO_NOPULL;
  HAL_GPIO_Init(B1_GPIO_Port, &GPIO_InitStruct);

  /*Configure GPIO pins : LD_U_Pin LD_D_Pin LD_L_Pin LD_R_Pin */
  GPIO_InitStruct.Pin = LD_U_Pin|LD_D_Pin|LD_L_Pin|LD_R_Pin;
  GPIO_InitStruct.Mode = GPIO_MODE_OUTPUT_PP;
  GPIO_InitStruct.Pull = GPIO_NOPULL;
  GPIO_InitStruct.Speed = GPIO_SPEED_FREQ_LOW;
  HAL_GPIO_Init(GPIOB, &GPIO_InitStruct);

}

void Error_Handler(void)
{
  __disable_irq();
  while (1)
  {
  }
}
